# FM33FH0XX register map
File version: 1.0
CPU: SC000 r1p0, little endian, no MPU, no FPU, 3 interrupt priority bits
Registers are 32-bit, read-write, reset 0x0 unless marked. A register's access mark holds for its fields unless they carry their own. Offsets are from the block's base; [hi:lo] are bit positions.

## SFU — SFU module information
Base 0x40002C00
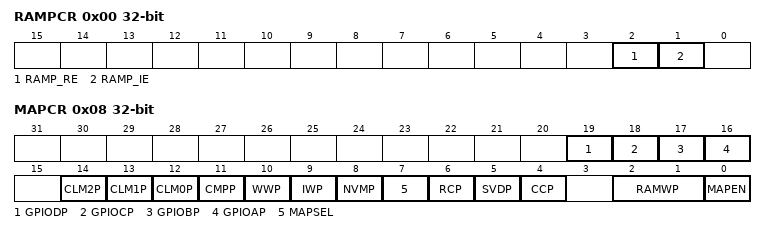
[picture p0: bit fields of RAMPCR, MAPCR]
0x00 RAMPCR
  [2] RAMP_RE — RAMP_RE field description
  [1] RAMP_IE — RAMP_IE field description
0x04 RAMPSR
  [1] RAMP_IF — RAMP_IF field description
0x08 MAPCR
  [19] GPIODP — GPIODP field description
  [18] GPIOCP — GPIOCP field description
  [17] GPIOBP — GPIOBP field description
  [16] GPIOAP — GPIOAP field description
  [14] CLM2P — CLM2P field description
  [13] CLM1P — CLM1P field description
  [12] CLM0P — CLM0P field description
  [11] CMPP — CMPP field description
  [10] WWP — WWP field description
  [9] IWP — IWP field description
  [8] NVMP — NVMP field description
  [7] MAPSEL — MAPSEL field description
  [6] RCP — RCP field description
  [5] SVDP — SVDP field description
  [4] CCP — CCP field description
  [2:1] RAMWP — RAMWP field description
  [0] MAPEN — MAPEN field description
0x0C MAPISR
  [0] MAPIF — MAPIF field description

## SPI0 — SPI0 module information
Base 0x40019000
Same registers: SPI2 0x40010800, SPI1 0x40018C00
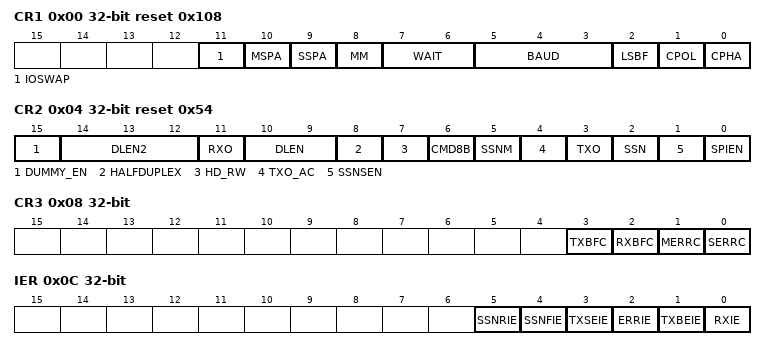
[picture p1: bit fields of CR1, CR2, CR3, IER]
0x00 CR1 reset 0x108
  [11] IOSWAP — IOSWAP field description
  [10] MSPA — MSPA field description
  [9] SSPA — SSPA field description
  [8] MM — MM field description
  [7:6] WAIT — WAIT field description
  [5:3] BAUD — BAUD field description
  [2] LSBF — LSBF field description
  [1] CPOL — CPOL field description
  [0] CPHA — CPHA field description
0x04 CR2 reset 0x54
  [15] DUMMY_EN — DUMMY_EN field description
  [14:12] DLEN2 — DLEN2 field description
  [11] RXO — RXO field description
  [10:9] DLEN — DLEN field description
  [8] HALFDUPLEX — HALFDUPLEX field description
  [7] HD_RW — HD_RW field description
  [6] CMD8B — CMD8B field description
  [5] SSNM — SSNM field description
  [4] TXO_AC — TXO_AC field description
  [3] TXO — TXO field description
  [2] SSN — SSN field description
  [1] SSNSEN — SSNSEN field description
  [0] SPIEN — SPIEN field description
0x08 CR3
  [3] TXBFC wo — TXBFC field description
  [2] RXBFC wo — RXBFC field description
  [1] MERRC wo — MERRC field description
  [0] SERRC wo — SERRC field description
0x0C IER
  [5] SSNRIE — SSNRIE field description
  [4] SSNFIE — SSNFIE field description
  [3] TXSEIE — TXSEIE field description
  [2] ERRIE — ERRIE field description
  [1] TXBEIE — TXBEIE field description
  [0] RXIE — RXIE field description
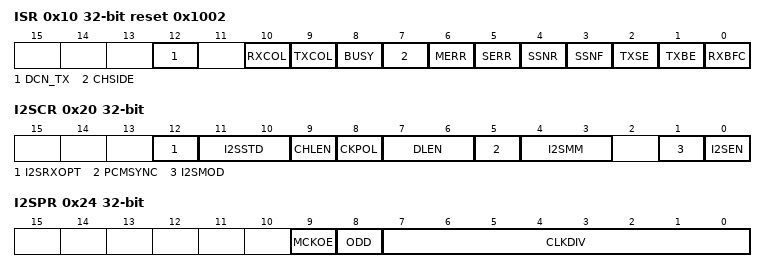
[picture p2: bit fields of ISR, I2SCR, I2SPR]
0x10 ISR reset 0x1002
  [12] DCN_TX — DCN_TX field description
  [10] RXCOL — RXCOL field description
  [9] TXCOL — TXCOL field description
  [8] BUSY ro — BUSY field description
  [7] CHSIDE ro — CHSIDE field description
  [6] MERR ro — MERR field description
  [5] SERR ro — SERR field description
  [4] SSNR — SSNR field description
  [3] SSNF — SSNF field description
  [2] TXSE — TXSE field description
  [1] TXBE ro — TXBE field description
  [0] RXBFC ro — RXBFC field description
0x14 TXBUF
  [31:0] TXBUF wo — TXBUF field description
0x18 RXBUF
  [31:0] RXBUF ro — RXBUF field description
0x20 I2SCR
  [12] I2SRXOPT — I2SRXOPT field description
  [11:10] I2SSTD — I2SSTD field description
  [9] CHLEN — CHLEN field description
  [8] CKPOL — CKPOL field description
  [7:6] DLEN — DLEN field description
  [5] PCMSYNC — PCMSYNC field description
  [4:3] I2SMM — I2SMM field description
  [1] I2SMOD — I2SMOD field description
  [0] I2SEN — I2SEN field description
0x24 I2SPR
  [9] MCKOE — MCKOE field description
  [8] ODD — ODD field description
  [7:0] CLKDIV — CLKDIV field description

## SVD — SVD module information
Base 0x4001A800
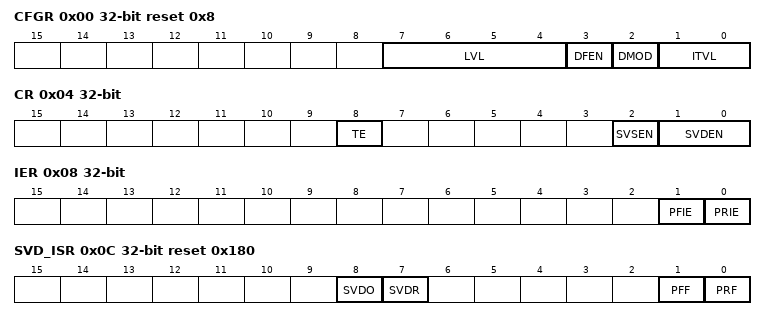
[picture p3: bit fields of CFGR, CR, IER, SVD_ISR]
0x00 CFGR reset 0x8
  [7:4] LVL — LVL field description
  [3] DFEN — DFEN field description
  [2] DMOD — DMOD field description
  [1:0] ITVL — ITVL field description
0x04 CR
  [8] TE — TE field description
  [2] SVSEN — SVSEN field description
  [1:0] SVDEN — SVDEN field description
0x08 IER
  [1] PFIE — PFIE field description
  [0] PRIE — PRIE field description
0x0C SVD_ISR reset 0x180
  [8] SVDO ro — SVDO field description
  [7] SVDR ro — SVDR field description
  [1] PFF — PFF field description
  [0] PRF — PRF field description
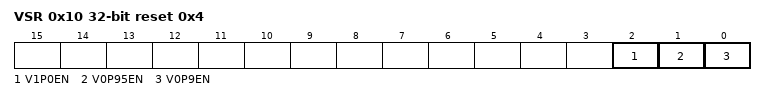
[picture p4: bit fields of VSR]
0x10 VSR reset 0x4
  [2] V1P0EN — V1P0EN field description
  [1] V0P95EN — V0P95EN field description
  [0] V0P9EN — V0P9EN field description
